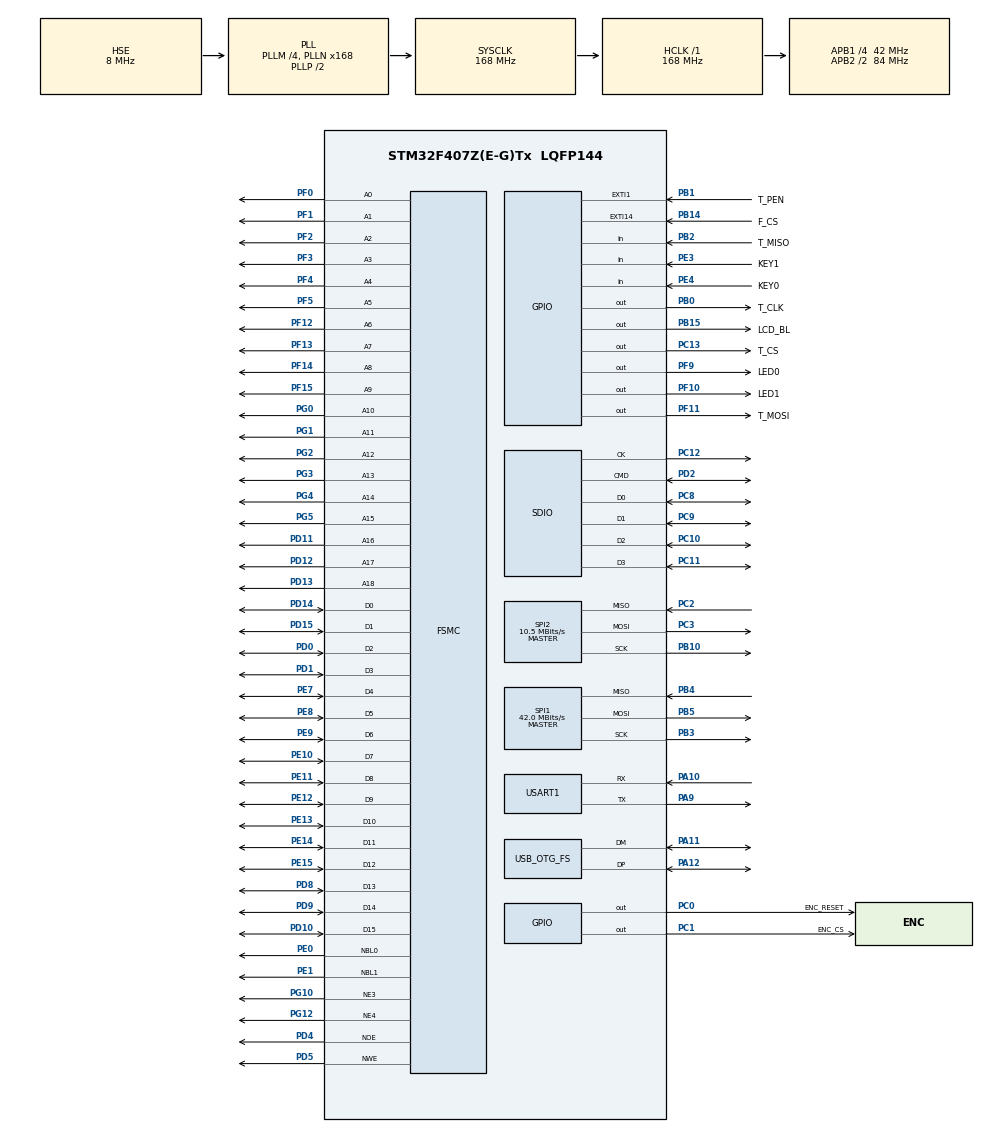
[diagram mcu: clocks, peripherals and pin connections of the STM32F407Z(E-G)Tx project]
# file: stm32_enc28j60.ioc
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FSMC.AddressSetupTime1=2
FSMC.DataSetupTime1=15
FSMC.ExtendedAddressSetupTime1=2
FSMC.ExtendedBusTurnAroundDuration1=3
FSMC.ExtendedDataSetupTime1=3
FSMC.ExtendedMode1=FSMC_EXTENDED_MODE_ENABLE
FSMC.ExtendedMode2=FSMC_EXTENDED_MODE_ENABLE
FSMC.WriteOperation2=FSMC_WRITE_OPERATION_ENABLE
Mcu.Family=STM32F4
Mcu.Name=STM32F407Z(E-G)Tx
Mcu.Package=LQFP144
NVIC.EXTI1_IRQn=true\:0\:0\:false\:false\:true\:true\:true\:true
NVIC.PriorityGroup=NVIC_PRIORITYGROUP_4
NVIC.TIM1_UP_TIM10_IRQn=true\:15\:0\:false\:false\:true\:false\:true\:true
NVIC.TimeBase=TIM1_UP_TIM10_IRQn
NVIC.TimeBaseIP=TIM1
PA10.Mode=Asynchronous
PA10.Signal=USART1_RX
PA11.Mode=Host_Only
PA11.Signal=USB_OTG_FS_DM
PA12.Mode=Host_Only
PA12.Signal=USB_OTG_FS_DP
PA13.Mode=Serial_Wire
PA13.Signal=SYS_JTMS-SWDIO
PA14.Mode=Serial_Wire
PA14.Signal=SYS_JTCK-SWCLK
PA9.Mode=Asynchronous
PA9.Signal=USART1_TX
PB0.GPIO_Label=T_CLK
PB0.GPIO_PuPd=GPIO_NOPULL
PB0.Signal=GPIO_Output
PB1.GPIO_Label=T_PEN
PB1.GPIO_ModeDefaultEXTI=GPIO_MODE_IT_RISING_FALLING
PB1.GPIO_PuPd=GPIO_PULLUP
PB1.Signal=GPXTI1
PB10.Mode=Full_Duplex_Master
PB10.Signal=SPI2_SCK
PB14.GPIO_Label=F_CS
PB14.Signal=GPXTI14
PB15.GPIO_Label=LCD_BL
PB15.Signal=GPIO_Output
PB2.GPIO_Label=T_MISO
PB2.Signal=GPIO_Input
PB3.Mode=Full_Duplex_Master
PB3.Signal=SPI1_SCK
PB4.Mode=Full_Duplex_Master
PB4.Signal=SPI1_MISO
PB5.Mode=Full_Duplex_Master
PB5.Signal=SPI1_MOSI
PC0.GPIO_Label=ENC_RESET
PC0.Signal=GPIO_Output
PC1.GPIO_Label=ENC_CS
PC1.Signal=GPIO_Output
PC10.Mode=SD_4_bits_Wide_bus
PC10.Signal=SDIO_D2
PC11.Mode=SD_4_bits_Wide_bus
PC11.Signal=SDIO_D3
PC12.Mode=SD_4_bits_Wide_bus
PC12.Signal=SDIO_CK
PC13-ANTI_TAMP.GPIO_Label=T_CS
PC13-ANTI_TAMP.GPIO_PuPd=GPIO_PULLUP
PC13-ANTI_TAMP.GPIO_Speed=GPIO_SPEED_FREQ_LOW
PC13-ANTI_TAMP.PinState=GPIO_PIN_SET
PC13-ANTI_TAMP.Signal=GPIO_Output
PC14-OSC32_IN.Mode=LSE-External-Oscillator
PC14-OSC32_IN.Signal=RCC_OSC32_IN
PC15-OSC32_OUT.Mode=LSE-External-Oscillator
PC15-OSC32_OUT.Signal=RCC_OSC32_OUT
PC2.Mode=Full_Duplex_Master
PC2.Signal=SPI2_MISO
PC3.Mode=Full_Duplex_Master
PC3.Signal=SPI2_MOSI
PC8.Mode=SD_4_bits_Wide_bus
PC8.Signal=SDIO_D0
PC9.Mode=SD_4_bits_Wide_bus
PC9.Signal=SDIO_D1
PD0.Signal=FSMC_D2_DA2
PD1.Signal=FSMC_D3_DA3
PD10.Signal=FSMC_D15_DA15
PD11.Signal=FSMC_A16_CLE
PD12.Signal=FSMC_A17_ALE
PD13.Signal=FSMC_A18
PD14.Signal=FSMC_D0_DA0
PD15.Signal=FSMC_D1_DA1
PD2.Mode=SD_4_bits_Wide_bus
PD2.Signal=SDIO_CMD
PD4.Signal=FSMC_NOE
PD5.Signal=FSMC_NWE
PD8.Signal=FSMC_D13_DA13
PD9.Signal=FSMC_D14_DA14
PE0.Signal=FSMC_NBL0
PE1.Signal=FSMC_NBL1
PE10.Signal=FSMC_D7_DA7
PE11.Signal=FSMC_D8_DA8
PE12.Signal=FSMC_D9_DA9
PE13.Signal=FSMC_D10_DA10
PE14.Signal=FSMC_D11_DA11
PE15.Signal=FSMC_D12_DA12
PE3.GPIO_Label=KEY1
PE3.GPIO_PuPd=GPIO_PULLUP
PE3.Signal=GPIO_Input
PE4.GPIO_Label=KEY0
PE4.GPIO_PuPd=GPIO_PULLUP
PE4.Signal=GPIO_Input
PE7.Signal=FSMC_D4_DA4
PE8.Signal=FSMC_D5_DA5
PE9.Signal=FSMC_D6_DA6
PF0.Signal=FSMC_A0
PF1.Signal=FSMC_A1
PF10.GPIO_Label=LED1
PF10.Signal=GPIO_Output
PF11.GPIO_Label=T_MOSI
PF11.Signal=GPIO_Output
PF12.Signal=FSMC_A6
PF13.Signal=FSMC_A7
PF14.Signal=FSMC_A8
PF15.Signal=FSMC_A9
PF2.Signal=FSMC_A2
PF3.Signal=FSMC_A3
PF4.Signal=FSMC_A4
PF5.Signal=FSMC_A5
PF9.GPIO_Label=LED0
PF9.Signal=GPIO_Output
PG0.Signal=FSMC_A10
PG1.Signal=FSMC_A11
PG10.Mode=NorPsramChipSelect3_2
PG10.Signal=FSMC_NE3
PG12.Mode=NorPsramChipSelect4_1
PG12.Signal=FSMC_NE4
PG2.Signal=FSMC_A12
PG3.Signal=FSMC_A13
PG4.Signal=FSMC_A14
PG5.Signal=FSMC_A15
PH0-OSC_IN.Mode=HSE-External-Oscillator
PH0-OSC_IN.Signal=RCC_OSC_IN
PH1-OSC_OUT.Mode=HSE-External-Oscillator
PH1-OSC_OUT.Signal=RCC_OSC_OUT
ProjectManager.HeapSize=0x2000
ProjectManager.StackSize=0x2000
ProjectManager.TargetToolchain=STM32CubeIDE
RCC.48MHZClocksFreq_Value=48000000
RCC.AHBFreq_Value=168000000
RCC.APB1CLKDivider=RCC_HCLK_DIV4
RCC.APB1Freq_Value=42000000
RCC.APB1TimFreq_Value=84000000
RCC.APB2CLKDivider=RCC_HCLK_DIV2
RCC.APB2Freq_Value=84000000
RCC.APB2TimFreq_Value=168000000
RCC.CortexFreq_Value=168000000
RCC.HCLKFreq_Value=168000000
RCC.HSE_VALUE=8000000
RCC.HSI_VALUE=16000000
RCC.PLLM=4
RCC.PLLN=168
RCC.PLLQ=7
RCC.SYSCLKFreq_VALUE=168000000
RCC.SYSCLKSource=RCC_SYSCLKSOURCE_PLLCLK
RCC.VCOOutputFreq_Value=336000000
SH.FSMC_A0.0=FSMC_A0,19b-a2
SH.FSMC_A1.0=FSMC_A1,19b-a2
SH.FSMC_A10.0=FSMC_A10,19b-a2
SH.FSMC_A11.0=FSMC_A11,19b-a2
SH.FSMC_A12.0=FSMC_A12,19b-a2
SH.FSMC_A13.0=FSMC_A13,19b-a2
SH.FSMC_A14.0=FSMC_A14,19b-a2
SH.FSMC_A15.0=FSMC_A15,19b-a2
SH.FSMC_A16_CLE.0=FSMC_A16,19b-a2
SH.FSMC_A17_ALE.0=FSMC_A17,19b-a2
SH.FSMC_A18.0=FSMC_A18,19b-a2
SH.FSMC_A2.0=FSMC_A2,19b-a2
SH.FSMC_A3.0=FSMC_A3,19b-a2
SH.FSMC_A4.0=FSMC_A4,19b-a2
SH.FSMC_A5.0=FSMC_A5,19b-a2
SH.FSMC_A6.0=FSMC_A6,A6_1
SH.FSMC_A6.1=FSMC_A6,19b-a2
SH.FSMC_A7.0=FSMC_A7,19b-a2
SH.FSMC_A8.0=FSMC_A8,19b-a2
SH.FSMC_A9.0=FSMC_A9,19b-a2
SH.FSMC_D0_DA0.0=FSMC_D0,16b-d1
SH.FSMC_D0_DA0.1=FSMC_D0,16b-d2
SH.FSMC_D10_DA10.0=FSMC_D10,16b-d1
SH.FSMC_D10_DA10.1=FSMC_D10,16b-d2
SH.FSMC_D11_DA11.0=FSMC_D11,16b-d1
SH.FSMC_D11_DA11.1=FSMC_D11,16b-d2
SH.FSMC_D12_DA12.0=FSMC_D12,16b-d1
SH.FSMC_D12_DA12.1=FSMC_D12,16b-d2
SH.FSMC_D13_DA13.0=FSMC_D13,16b-d1
SH.FSMC_D13_DA13.1=FSMC_D13,16b-d2
SH.FSMC_D14_DA14.0=FSMC_D14,16b-d1
SH.FSMC_D14_DA14.1=FSMC_D14,16b-d2
SH.FSMC_D15_DA15.0=FSMC_D15,16b-d1
SH.FSMC_D15_DA15.1=FSMC_D15,16b-d2
SH.FSMC_D1_DA1.0=FSMC_D1,16b-d1
SH.FSMC_D1_DA1.1=FSMC_D1,16b-d2
SH.FSMC_D2_DA2.0=FSMC_D2,16b-d1
SH.FSMC_D2_DA2.1=FSMC_D2,16b-d2
SH.FSMC_D3_DA3.0=FSMC_D3,16b-d1
SH.FSMC_D3_DA3.1=FSMC_D3,16b-d2
SH.FSMC_D4_DA4.0=FSMC_D4,16b-d1
SH.FSMC_D4_DA4.1=FSMC_D4,16b-d2
SH.FSMC_D5_DA5.0=FSMC_D5,16b-d1
SH.FSMC_D5_DA5.1=FSMC_D5,16b-d2
SH.FSMC_D6_DA6.0=FSMC_D6,16b-d1
SH.FSMC_D6_DA6.1=FSMC_D6,16b-d2
SH.FSMC_D7_DA7.0=FSMC_D7,16b-d1
SH.FSMC_D7_DA7.1=FSMC_D7,16b-d2
SH.FSMC_D8_DA8.0=FSMC_D8,16b-d1
SH.FSMC_D8_DA8.1=FSMC_D8,16b-d2
SH.FSMC_D9_DA9.0=FSMC_D9,16b-d1
SH.FSMC_D9_DA9.1=FSMC_D9,16b-d2
SH.FSMC_NBL0.0=FSMC_NBL0,2ByteEnable2
SH.FSMC_NBL1.0=FSMC_NBL1,2ByteEnable2
SH.FSMC_NOE.0=FSMC_NOE,Lcd1
SH.FSMC_NOE.1=FSMC_NOE,Sram2
SH.FSMC_NWE.0=FSMC_NWE,Lcd1
SH.FSMC_NWE.1=FSMC_NWE,Sram2
SPI1.CalculateBaudRate=42.0 MBits/s
SPI1.Direction=SPI_DIRECTION_2LINES
SPI1.Mode=SPI_MODE_MASTER
SPI1.VirtualType=VM_MASTER
SPI2.BaudRatePrescaler=SPI_BAUDRATEPRESCALER_4
SPI2.CalculateBaudRate=10.5 MBits/s
SPI2.Direction=SPI_DIRECTION_2LINES
SPI2.Mode=SPI_MODE_MASTER
SPI2.VirtualType=VM_MASTER
USART1.VirtualMode=VM_ASYNC
USB_OTG_FS.VirtualMode=Host_Only
USB_OTG_FS.phy_itface=HCD_PHY_EMBEDDED
VP_CRC_VS_CRC.Mode=CRC_Activate
VP_RNG_VS_RNG.Mode=RNG_Activate
VP_SYS_VS_tim1.Mode=TIM1
board=custom

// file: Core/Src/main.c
/* USER CODE BEGIN Header */
/**
  ******************************************************************************
  * @file           : main.c
  * @brief          : Main program body
  ******************************************************************************
  * @attention
  *
  * Copyright (c) 2024 STMicroelectronics.
  * All rights reserved.
  *
  * This software is licensed under terms that can be found in the LICENSE file
  * in the root directory of this software component.
  * If no LICENSE file comes with this software, it is provided AS-IS.
  *
  ******************************************************************************
  */
/* USER CODE END Header */
#include "main.h"
#include "crc.h"
#include "rng.h"
#include "sdio.h"
#include "spi.h"
#include "usart.h"
#include "usb_otg.h"
#include "gpio.h"
#include "fsmc.h"

/* USER CODE BEGIN Includes */
#include <stdio.h>
#include "../net/net.h"
#include "../led/led.h"
/* USER CODE END Includes */

/* USER CODE BEGIN PD */
#define PUTCHAR_PROTOTYPE int __io_putchar(int ch)
/* USER CODE END PD */

void SystemClock_Config(void);

int main(void)
{

  /* MCU Configuration--------------------------------------------------------*/

  /* Reset of all peripherals, Initializes the Flash interface and the Systick. */
  HAL_Init();

  /* Configure the system clock */
  SystemClock_Config();

  /* Initialize all configured peripherals */
  MX_GPIO_Init();
  MX_FSMC_Init();
  MX_RNG_Init();
  MX_USART1_UART_Init();
  MX_CRC_Init();
  MX_USB_OTG_FS_HCD_Init();
  MX_SPI1_Init();
  MX_SPI2_Init();
  MX_SDIO_SD_Init();

  /* Infinite loop */
  while (1)
  {

    /* USER CODE BEGIN 3 */
	  printf("%s%sNetworking with ecn28j69\r\n%s", COLOR_RESET, COLOR_GREEN, COLOR_RESET);
	  led0_off();
	  led1_off();

	  printf("reset ecn28j69\r\n");
	  net_init();

	  printf("start net pooling\r\n");
	  while (1)
	  {
		  net_pool();
	  }

  }
  /* USER CODE END 3 */
}

void SystemClock_Config(void)
{
  RCC_OscInitTypeDef RCC_OscInitStruct = {0};
  RCC_ClkInitTypeDef RCC_ClkInitStruct = {0};

  /** Configure the main internal regulator output voltage
  */
  __HAL_RCC_PWR_CLK_ENABLE();
  __HAL_PWR_VOLTAGESCALING_CONFIG(PWR_REGULATOR_VOLTAGE_SCALE1);

  /** Initializes the RCC Oscillators according to the specified parameters
  * in the RCC_OscInitTypeDef structure.
  */
  RCC_OscInitStruct.OscillatorType = RCC_OSCILLATORTYPE_HSE;
  RCC_OscInitStruct.HSEState = RCC_HSE_ON;
  RCC_OscInitStruct.PLL.PLLState = RCC_PLL_ON;
  RCC_OscInitStruct.PLL.PLLSource = RCC_PLLSOURCE_HSE;
  RCC_OscInitStruct.PLL.PLLM = 4;
  RCC_OscInitStruct.PLL.PLLN = 168;
  RCC_OscInitStruct.PLL.PLLP = RCC_PLLP_DIV2;
  RCC_OscInitStruct.PLL.PLLQ = 7;
  if (HAL_RCC_OscConfig(&RCC_OscInitStruct) != HAL_OK)
  {
    Error_Handler();
  }

  /** Initializes the CPU, AHB and APB buses clocks
  */
  RCC_ClkInitStruct.ClockType = RCC_CLOCKTYPE_HCLK|RCC_CLOCKTYPE_SYSCLK
                              |RCC_CLOCKTYPE_PCLK1|RCC_CLOCKTYPE_PCLK2;
  RCC_ClkInitStruct.SYSCLKSource = RCC_SYSCLKSOURCE_PLLCLK;
  RCC_ClkInitStruct.AHBCLKDivider = RCC_SYSCLK_DIV1;
  RCC_ClkInitStruct.APB1CLKDivider = RCC_HCLK_DIV4;
  RCC_ClkInitStruct.APB2CLKDivider = RCC_HCLK_DIV2;

  if (HAL_RCC_ClockConfig(&RCC_ClkInitStruct, FLASH_LATENCY_5) != HAL_OK)
  {
    Error_Handler();
  }
}

/* USER CODE BEGIN 4 */
PUTCHAR_PROTOTYPE
{
  /* Place your implementation of fputc here */
  /* e.g. write a character to the USART1 and Loop until the end of transmission */
  HAL_UART_Transmit(&huart1, (uint8_t *)&ch, 1, 0xFFFF);
  return ch;
}

/* USER CODE END 4 */

void HAL_TIM_PeriodElapsedCallback(TIM_HandleTypeDef *htim)
{
  if (htim->Instance == TIM1) {
    HAL_IncTick();
  }
}

void Error_Handler(void)
{
  __disable_irq();
  while (1)
  {
  }
}
